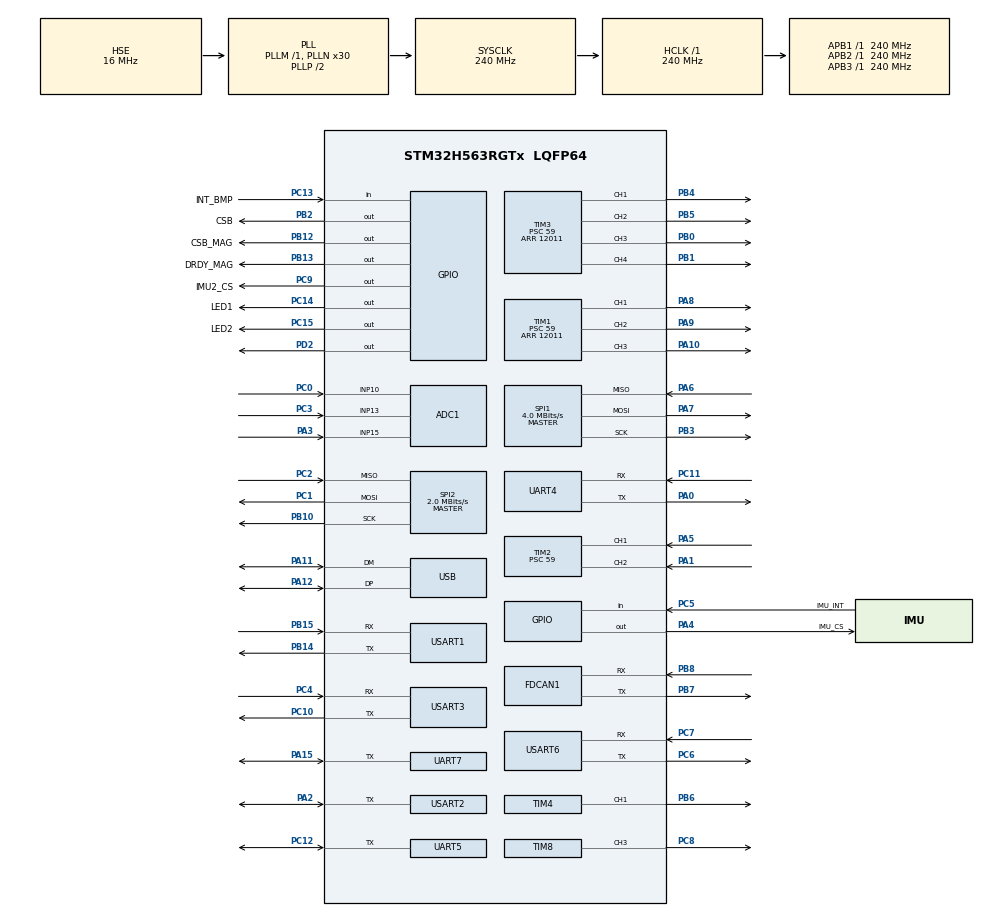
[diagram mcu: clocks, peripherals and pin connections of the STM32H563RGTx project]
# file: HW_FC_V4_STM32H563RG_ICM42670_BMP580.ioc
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ADC1.Channel-0\#ChannelRegularConversion=ADC_CHANNEL_13
ADC1.MonitoredBy-0\#ChannelRegularConversion=__NULL
ADC1.NbrOfConversionFlag=1
ADC1.OffsetNumber-0\#ChannelRegularConversion=ADC_OFFSET_NONE
ADC1.Rank-0\#ChannelRegularConversion=1
ADC1.SamplingTime-0\#ChannelRegularConversion=ADC_SAMPLETIME_2CYCLES_5
ADC1.master=1
BOOTPATH.BootPathName=LEGACY
BOOTPATH.UserSelectedBootPath=LEGACY
CORTEX_M33_NS.userName=CORTEX_M33
FDCAN1.CalculateBaudRateNominal=333333
FDCAN1.CalculateTimeBitNominal=3000
FDCAN1.CalculateTimeQuantumNominal=1000.0
Mcu.Family=STM32H5
Mcu.Name=STM32H563RGTx
Mcu.Package=LQFP64
NVIC.PriorityGroup=NVIC_PRIORITYGROUP_4
NVIC.USART1_IRQn=true\:0\:0\:false\:false\:true\:true\:true\:true
NVIC.USART2_IRQn=true\:0\:0\:false\:false\:true\:true\:true\:true
PA0.Mode=Asynchronous
PA0.Signal=UART4_TX
PA1.Signal=S_TIM2_CH2
PA10.Signal=S_TIM1_CH3
PA11.Mode=Device
PA11.Signal=USB_DM
PA12.Mode=Device
PA12.Signal=USB_DP
PA13(JTMS/SWDIO).Signal=DEBUG_JTMS-SWDIO
PA14(JTCK/SWCLK).Signal=DEBUG_JTCK-SWCLK
PA15(JTDI).Mode=Half_duplex(single_wire_mode)
PA15(JTDI).Signal=UART7_TX
PA2.Mode=Half_duplex(single_wire_mode)
PA2.Signal=USART2_TX
PA3.Signal=ADCx_INP15
PA4.GPIO_Label=IMU_CS
PA4.Signal=GPIO_Output
PA5.Signal=S_TIM2_CH1
PA6.Mode=Full_Duplex_Master
PA6.Signal=SPI1_MISO
PA7.Mode=Full_Duplex_Master
PA7.Signal=SPI1_MOSI
PA8.Signal=S_TIM1_CH1
PA9.Signal=S_TIM1_CH2
PB0.Signal=S_TIM3_CH3
PB1.Signal=S_TIM3_CH4
PB10.Mode=Full_Duplex_Master
PB10.Signal=SPI2_SCK
PB12.GPIO_Label=CSB_MAG
PB12.Signal=GPIO_Output
PB13.GPIO_Label=DRDY_MAG
PB13.Signal=GPIO_Output
PB14.Mode=Asynchronous
PB14.Signal=USART1_TX
PB15.Mode=Asynchronous
PB15.Signal=USART1_RX
PB2.GPIO_Label=CSB
PB2.Signal=GPIO_Output
PB3(JTDO/TRACESWO).Mode=Full_Duplex_Master
PB3(JTDO/TRACESWO).Signal=SPI1_SCK
PB4(NJTRST).PinAttribute=Free
PB4(NJTRST).Signal=S_TIM3_CH1
PB5.PinAttribute=Free
PB5.Signal=S_TIM3_CH2
PB6.PinAttribute=Free
PB6.Signal=S_TIM4_CH1
PB7.Mode=FDCAN_Activate
PB7.Signal=FDCAN1_TX
PB8.Mode=FDCAN_Activate
PB8.Signal=FDCAN1_RX
PC0.Signal=ADCx_INP10
PC1.Mode=Full_Duplex_Master
PC1.Signal=SPI2_MOSI
PC10.Mode=Asynchronous
PC10.Signal=USART3_TX
PC11.Mode=Asynchronous
PC11.Signal=UART4_RX
PC12.Mode=Half_duplex(single_wire_mode)
PC12.Signal=UART5_TX
PC13.GPIO_Label=INT_BMP
PC13.Signal=GPIO_Input
PC14-OSC32_IN(OSC32_IN).GPIO_Label=LED1
PC14-OSC32_IN(OSC32_IN).Signal=GPIO_Output
PC15-OSC32_OUT(OSC32_OUT).GPIO_Label=LED2
PC15-OSC32_OUT(OSC32_OUT).Signal=GPIO_Output
PC2.Mode=Full_Duplex_Master
PC2.Signal=SPI2_MISO
PC3.Signal=ADCx_INP13
PC4.Mode=Asynchronous
PC4.Signal=USART3_RX
PC5.GPIO_Label=IMU_INT
PC5.Signal=GPIO_Input
PC6.Mode=Asynchronous
PC6.Signal=USART6_TX
PC7.Mode=Asynchronous
PC7.Signal=USART6_RX
PC8.Signal=S_TIM8_CH3
PC9.GPIO_Label=IMU2_CS
PC9.Signal=GPIO_Output
PD2.Signal=GPIO_Output
PH0-OSC_IN(PH0).Mode=HSE-External-Oscillator
PH0-OSC_IN(PH0).Signal=RCC_OSC_IN
PH1-OSC_OUT(PH1).Mode=HSE-External-Oscillator
PH1-OSC_OUT(PH1).Signal=RCC_OSC_OUT
ProjectManager.HeapSize=0x200
ProjectManager.StackSize=0x400
ProjectManager.TargetToolchain=STM32CubeIDE
RCC.ADCFreq_Value=240000000
RCC.AHBFreq_Value=240000000
RCC.APB1Freq_Value=240000000
RCC.APB1TimFreq_Value=240000000
RCC.APB2Freq_Value=240000000
RCC.APB2TimFreq_Value=240000000
RCC.APB3Freq_Value=240000000
RCC.CSI_VALUE=4000000
RCC.CortexFreq_Value=240000000
RCC.EPOD_VALUE=16000000
RCC.FLatency=FLASH_LATENCY_5
RCC.FLatency-AdvancedSettings=FLASH_LATENCY_5
RCC.HCLKFreq_Value=240000000
RCC.HSE_VALUE=16000000
RCC.HSI48_VALUE=48000000
RCC.HSI_VALUE=64000000
RCC.LSE_VALUE=32768
RCC.LSIRC_VALUE=32000
RCC.PLL1Q=4
RCC.PLL2Source=RCC_PLL2_SOURCE_HSI
RCC.PLLFRACN=0
RCC.PLLN=30
RCC.PLLSourceVirtual=RCC_PLL1_SOURCE_HSE
RCC.SPI1CLockSelection=RCC_SPI1CLKSOURCE_CLKP
RCC.SPI2CLockSelection=RCC_SPI2CLKSOURCE_CLKP
RCC.SYSCLKFreq_VALUE=240000000
RCC.SYSCLKSource=RCC_SYSCLKSOURCE_PLLCLK
RCC.USBFreq_Value=48000000
RCC.VCOOutputFreq_Value=480000000
SH.ADCx_INP10.0=ADC1_INP10,IN10-Single-Ended
SH.ADCx_INP13.0=ADC1_INP13,IN13-Single-Ended
SH.ADCx_INP15.0=ADC1_INP15,IN15-Single-Ended
SH.S_TIM1_CH1.0=TIM1_CH1,PWM Generation1 CH1
SH.S_TIM1_CH2.0=TIM1_CH2,PWM Generation2 CH2
SH.S_TIM1_CH3.0=TIM1_CH3,PWM Generation3 CH3
SH.S_TIM2_CH1.0=TIM2_CH1,Input_Capture1_from_TI1
SH.S_TIM2_CH2.0=TIM2_CH2,Input_Capture2_from_TI2
SH.S_TIM3_CH1.0=TIM3_CH1,PWM Generation1 CH1
SH.S_TIM3_CH2.0=TIM3_CH2,PWM Generation2 CH2
SH.S_TIM3_CH3.0=TIM3_CH3,PWM Generation3 CH3
SH.S_TIM3_CH4.0=TIM3_CH4,PWM Generation4 CH4
SH.S_TIM4_CH1.0=TIM4_CH1,PWM Generation1 CH1
SH.S_TIM8_CH3.0=TIM8_CH3,PWM Generation3 CH3
SPI1.BaudRatePrescaler=SPI_BAUDRATEPRESCALER_8
SPI1.CLKPhase=SPI_PHASE_1EDGE
SPI1.CLKPolarity=SPI_POLARITY_LOW
SPI1.CalculateBaudRate=4.0 MBits/s
SPI1.DataSize=SPI_DATASIZE_8BIT
SPI1.Direction=SPI_DIRECTION_2LINES
SPI1.Mode=SPI_MODE_MASTER
SPI1.VirtualType=VM_MASTER
SPI2.BaudRatePrescaler=SPI_BAUDRATEPRESCALER_16
SPI2.CalculateBaudRate=2.0 MBits/s
SPI2.DataSize=SPI_DATASIZE_8BIT
SPI2.Direction=SPI_DIRECTION_2LINES
SPI2.Mode=SPI_MODE_MASTER
SPI2.VirtualType=VM_MASTER
TIM1.Channel-PWM\ Generation1\ CH1=TIM_CHANNEL_1
TIM1.Channel-PWM\ Generation2\ CH2=TIM_CHANNEL_2
TIM1.Channel-PWM\ Generation3\ CH3=TIM_CHANNEL_3
TIM1.PeriodNoDither=12011
TIM1.Prescaler=59
TIM2.Channel-Input_Capture1_from_TI1=TIM_CHANNEL_1
TIM2.Channel-Input_Capture2_from_TI2=TIM_CHANNEL_2
TIM2.Prescaler=59
TIM3.Channel-PWM\ Generation1\ CH1=TIM_CHANNEL_1
TIM3.Channel-PWM\ Generation2\ CH2=TIM_CHANNEL_2
TIM3.Channel-PWM\ Generation3\ CH3=TIM_CHANNEL_3
TIM3.Channel-PWM\ Generation4\ CH4=TIM_CHANNEL_4
TIM3.PeriodNoDither=12011
TIM3.Prescaler=59
TIM4.Channel-PWM\ Generation1\ CH1=TIM_CHANNEL_1
TIM4.PeriodNoDither=7142
TIM4.Prescaler=59
TIM8.Channel-PWM\ Generation3\ CH3=TIM_CHANNEL_3
TIM8.PeriodNoDither=12011
TIM8.Prescaler=59
USART1.VirtualMode-Asynchronous=VM_ASYNC
USART2.VirtualMode-Half_duplex(single_wire_mode)=VM_ASYNC
USART3.VirtualMode-Asynchronous=VM_ASYNC
USART6.VirtualMode=VM_ASYNC
USB.VirtualMode=Device_Only
USBX.Core_System=1
USBX.USBD_CDCACM_EPIN_ADDR=2
USBX.USBD_CDCACM_EPOUT_ADDR=3
USBX.UX_DEVICE_CDC_ACM=1
USBX.UX_DEVICE_ENABLED_FS=1
USBX.UX_Device_CoreStack=1
USBX.UX_enabled_FS=1
VP_BOOTPATH_VS_BOOTPATH.Mode=BP_Activate
VP_CORTEX_M33_NS_VS_Hclk.Mode=Hclk_Mode
VP_GPDMA1_VS_GPDMACH0.Mode=SIMPLEREQUEST_GPDMACH0
VP_ICACHE_VS_ICACHE.Mode=DefaultMode
VP_MEMORYMAP_VS_MEMORYMAP.Mode=CurAppReg
VP_PWR_VS_LPOM.Mode=PowerOptimisation
VP_PWR_VS_SECSignals.Mode=Security/Privilege
VP_TIM1_VS_ClockSourceINT.Mode=Internal
VP_TIM2_VS_ClockSourceINT.Mode=Internal
VP_TIM3_VS_ClockSourceINT.Mode=Internal
VP_TIM4_VS_ClockSourceINT.Mode=Internal
VP_TIM8_VS_ClockSourceINT.Mode=Internal
VP_USBX_Core_System.Mode=Core_System
VP_USBX_UX\ Device\ CDC\ ACM\ Class_FS.Mode=UX_Device_class_CDC_ACM_FS_HS
VP_USBX_UX\ Device\ CoreStack_FS.Mode=UX_Device_CoreStack
board=custom

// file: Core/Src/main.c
/* USER CODE BEGIN Header */
/**
  ******************************************************************************
  * @file           : main.c
  * @brief          : Main program body
  ******************************************************************************
  * @attention
  *
  * Copyright (c) 2026 STMicroelectronics.
  * All rights reserved.
  *
  * This software is licensed under terms that can be found in the LICENSE file
  * in the root directory of this software component.
  * If no LICENSE file comes with this software, it is provided AS-IS.
  *
  ******************************************************************************
  */
/* USER CODE END Header */
#include "main.h"
#include "app_usbx.h"

/* USER CODE BEGIN Includes */
#include "bmp5.h"
#include "math.h"
#include "bmm150.h"
/* USER CODE END Includes */

ADC_HandleTypeDef hadc1;

FDCAN_HandleTypeDef hfdcan1;

DMA_HandleTypeDef handle_GPDMA1_Channel0;

TIM_HandleTypeDef htim8;

UART_HandleTypeDef huart4;
UART_HandleTypeDef huart5;
UART_HandleTypeDef huart7;
UART_HandleTypeDef huart1;
UART_HandleTypeDef huart2;
UART_HandleTypeDef huart3;
UART_HandleTypeDef huart6;

PCD_HandleTypeDef hpcd_USB_DRD_FS;

/* USER CODE BEGIN PV */
static struct bmp5_dev bmp580_dev;
static struct bmp5_osr_odr_press_config bmp580_cfg;
static volatile int8_t bmp580_init_status;
static volatile int8_t bmp580_read_status;
static volatile uint8_t bmp580_spi_error_stage;
static volatile uint8_t bmp580_spi_last_rx;
static float bmp580_temperature_c;
static float bmp580_pressure_pa;
static struct bmm150_dev bmm150_dev;
static volatile int8_t bmm150_init_status;
static volatile int8_t bmm150_read_status;
static int16_t bmm150_x;
static int16_t bmm150_y;
static int16_t bmm150_z;
static float bmm150_heading_deg;
static uint32_t bmp580_last_read_ms;
static uint32_t bmm150_last_read_ms;
/* USER CODE END PV */

void SystemClock_Config(void);
void PeriphCommonClock_Config(void);
static void MX_GPIO_Init(void);
static void MX_GPDMA1_Init(void);
static void MX_SPI1_Init(void);
static void MX_SPI2_Init(void);
static void MX_TIM1_Init(void);
static void MX_TIM2_Init(void);
static void MX_TIM3_Init(void);
static void MX_TIM4_Init(void);
static void MX_UART4_Init(void);
static void MX_UART5_Init(void);
static void MX_USART1_UART_Init(void);
static void MX_USART2_UART_Init(void);
static void MX_USART3_UART_Init(void);
static void MX_USB_PCD_Init(void);
static void MX_ADC1_Init(void);
static void MX_FDCAN1_Init(void);
static void MX_TIM8_Init(void);
static void MX_UART7_Init(void);
static void MX_USART6_UART_Init(void);
static void MX_ICACHE_Init(void);

/* USER CODE BEGIN 0 */
/*
 * BMP580 connection (SPI2):
 * PB10 = SCK
 * PC1  = MOSI / SDI
 * PC2  = MISO / SDO
 * PB2  = CSB (active LOW)
 * PC13 = INT_BMP (currently not used; polling mode is used)
 *
 * SPI mode: CPOL = LOW, CPHA = 1st edge, 8-bit, MSB first.
 */
#define BMP580_SPI_TIMEOUT  100000U
static void bmp580_spi_clear_flags(void)
{
    LL_SPI_ClearFlag_EOT(SPI1);
    LL_SPI_ClearFlag_TXTF(SPI1);
    LL_SPI_ClearFlag_UDR(SPI1);
    LL_SPI_ClearFlag_OVR(SPI1);
    LL_SPI_ClearFlag_FRE(SPI1);
    LL_SPI_ClearFlag_MODF(SPI1);
    LL_SPI_ClearFlag_SUSP(SPI1);
}
static void bmp580_spi_abort(void)
{
    LL_GPIO_SetOutputPin(CSB_GPIO_Port, CSB_Pin); /* CSB = 1 */

    LL_SPI_Disable(SPI1);
    bmp580_spi_clear_flags();
}

static int8_t bmp580_spi_start(uint32_t bytes)
{
    LL_SPI_Disable(SPI1);
    bmp580_spi_clear_flags();
    LL_SPI_SetTransferSize(SPI1, bytes);
    LL_GPIO_ResetOutputPin(CSB_GPIO_Port, CSB_Pin); /* CSB = 0 */
    LL_SPI_Enable(SPI1);
    LL_SPI_StartMasterTransfer(SPI1);
    return 0;
}

static int8_t bmp580_spi_txrx_byte(uint8_t tx, uint8_t *rx)
{
    uint32_t timeout = BMP580_SPI_TIMEOUT;

    while (!LL_SPI_IsActiveFlag_TXP(SPI1))
    {
        if (--timeout == 0U)
        {
            bmp580_spi_error_stage = 1;  /* TXP timeout */
            return -1;
        }
    }

    LL_SPI_TransmitData8(SPI1, tx);

    timeout = BMP580_SPI_TIMEOUT;

    while (!LL_SPI_IsActiveFlag_RXP(SPI1))
    {
        if (--timeout == 0U)
        {
            bmp580_spi_error_stage = 2;  /* RXP timeout */
            return -1;
        }
    }

    *rx = LL_SPI_ReceiveData8(SPI1);
    bmp580_spi_last_rx = *rx;
    return 0;
}

static int8_t bmp580_spi_finish(void)
{
    uint32_t timeout = BMP580_SPI_TIMEOUT;
    while (!LL_SPI_IsActiveFlag_EOT(SPI1))
    {
        if (--timeout == 0U)
        {
            bmp580_spi_error_stage = 3;
            bmp580_spi_abort();
            return -1;
        }
    }
    LL_GPIO_SetOutputPin(CSB_GPIO_Port, CSB_Pin); /* CSB = 1 */
    LL_SPI_ClearFlag_EOT(SPI1);
    LL_SPI_ClearFlag_TXTF(SPI1);
    LL_SPI_Disable(SPI1);

    return 0;
}

static BMP5_INTF_RET_TYPE bmp580_spi_read(uint8_t reg_addr,  uint8_t *data, uint32_t len,
void *intf_ptr)
{
    uint8_t dummy;
    uint32_t i;
    (void)intf_ptr;
    if ((data == NULL) || (len == 0U)) return -1;
    if (bmp580_spi_start(len + 1U) != 0) return -1;
    if (bmp580_spi_txrx_byte(reg_addr, &dummy) != 0)
    {
        bmp580_spi_abort();return -1;
    }

    for (i = 0; i < len; i++)
    {
        if (bmp580_spi_txrx_byte(0x00U, &data[i]) != 0)
        {
            bmp580_spi_abort();
            return -1;
        }
    }

    return bmp580_spi_finish();
}

static BMP5_INTF_RET_TYPE bmp580_spi_write(uint8_t reg_addr, const uint8_t *data, uint32_t len, void *intf_ptr)
{
    uint8_t dummy;
    uint32_t i;
    (void)intf_ptr;
    if ((data == NULL) || (len == 0U))
        return -1;
    if (bmp580_spi_start(len + 1U) != 0)
        return -1;
    if (bmp580_spi_txrx_byte(reg_addr, &dummy) != 0)
    {
        bmp580_spi_abort();
        return -1;
    }
    for (i = 0; i < len; i++)
    {
        if (bmp580_spi_txrx_byte(data[i], &dummy) != 0)
        {
            bmp580_spi_abort();
            return -1;
        }
    }
    return bmp580_spi_finish();
}

static void bmp580_delay_us(uint32_t period, void *intf_ptr)
{
    (void)intf_ptr;

    if (period > 0U)
        HAL_Delay((period + 999U) / 1000U);
}
static int8_t BMP580_Init(void)
{
    int8_t rslt;
    struct bmp5_iir_config iir_cfg = {0};
    LL_GPIO_SetOutputPin(CSB_GPIO_Port, CSB_Pin);
    bmp580_dev.intf = BMP5_SPI_INTF;
    bmp580_dev.read = bmp580_spi_read;
    bmp580_dev.write = bmp580_spi_write;
    bmp580_dev.delay_us = bmp580_delay_us;
    bmp580_dev.intf_ptr = NULL;
    rslt = bmp5_init(&bmp580_dev);
    if (rslt == BMP5_E_NVM_NOT_READY)
    {
        uint8_t chip_id = 0;

        rslt = bmp5_get_regs(BMP5_REG_CHIP_ID, &chip_id, 1U, &bmp580_dev);

        if ((rslt == BMP5_OK) &&
            ((chip_id == BMP5_CHIP_ID_PRIM) || (chip_id == BMP5_CHIP_ID_SEC)))
        {
            bmp580_dev.chip_id = chip_id;
            rslt = BMP5_OK;
        }
    }

    if (rslt != BMP5_OK)
        return rslt;
    rslt = bmp5_set_power_mode(BMP5_POWERMODE_STANDBY, &bmp580_dev);
    if (rslt != BMP5_OK)
        return rslt;

    bmp580_cfg.press_en = BMP5_ENABLE;
    bmp580_cfg.osr_t = BMP5_OVERSAMPLING_64X;
    bmp580_cfg.osr_p = BMP5_OVERSAMPLING_4X;
    bmp580_cfg.odr = BMP5_ODR_50_HZ;

    rslt = bmp5_set_osr_odr_press_config(&bmp580_cfg, &bmp580_dev);
    if (rslt != BMP5_OK)
        return rslt;

    iir_cfg.set_iir_t = BMP5_IIR_FILTER_COEFF_1;
    iir_cfg.set_iir_p = BMP5_IIR_FILTER_COEFF_1;
    iir_cfg.shdw_set_iir_t = BMP5_ENABLE;
    iir_cfg.shdw_set_iir_p = BMP5_ENABLE;

    rslt = bmp5_set_iir_config(&iir_cfg, &bmp580_dev);
    if (rslt != BMP5_OK)
        return rslt;

    return bmp5_set_power_mode(BMP5_POWERMODE_NORMAL, &bmp580_dev);
}

static int8_t BMP580_Read(float *temperature_c, float *pressure_pa)
{
    struct bmp5_sensor_data data;
    int8_t rslt;

    rslt = bmp5_get_sensor_data(&data, &bmp580_cfg, &bmp580_dev);
    if (rslt == BMP5_OK)
    {
        *temperature_c = data.temperature;
        *pressure_pa = data.pressure;
    }

    return rslt;
}
static void bmm150_spi_abort(void)
{
    LL_GPIO_SetOutputPin(CSB_MAG_GPIO_Port, CSB_MAG_Pin);
    LL_SPI_Disable(SPI1);
    bmp580_spi_clear_flags();
}

static int8_t bmm150_spi_start(uint32_t bytes)
{
    if ((bytes == 0U) || (bytes > 65535U))
        return BMM150_E_COM_FAIL;

    LL_SPI_Disable(SPI1);
    bmp580_spi_clear_flags();
    LL_SPI_SetTransferSize(SPI1, bytes);

    LL_GPIO_SetOutputPin(CSB_GPIO_Port, CSB_Pin);
    LL_GPIO_SetOutputPin(IMU_CS_GPIO_Port, IMU_CS_Pin);
    LL_GPIO_SetOutputPin(GPIOC, IMU2_CS_Pin);

    LL_GPIO_ResetOutputPin(CSB_MAG_GPIO_Port, CSB_MAG_Pin);

    LL_SPI_Enable(SPI1);
    LL_SPI_StartMasterTransfer(SPI1);

    return BMM150_OK;
}

static int8_t bmm150_spi_finish(void)
{
    uint32_t timeout = BMP580_SPI_TIMEOUT;

    while (!LL_SPI_IsActiveFlag_EOT(SPI1))
    {
        if (--timeout == 0U)
        {
            bmm150_spi_abort();
            return BMM150_E_COM_FAIL;
        }
    }

    LL_GPIO_SetOutputPin(CSB_MAG_GPIO_Port, CSB_MAG_Pin);
    LL_SPI_ClearFlag_EOT(SPI1);
    LL_SPI_ClearFlag_TXTF(SPI1);
    LL_SPI_Disable(SPI1);

    return BMM150_OK;
}

static BMM150_INTF_RET_TYPE bmm150_spi_read(uint8_t reg_addr, uint8_t *data, uint32_t len, void *intf_ptr)
{
    uint8_t dummy;
    uint32_t i;

    (void)intf_ptr;

    if ((data == NULL) || (len == 0U))
        return BMM150_E_NULL_PTR;

    if (bmm150_spi_start(len + 1U) != BMM150_OK)
        return BMM150_E_COM_FAIL;

    /* BMM150 library da tu them bit read 0x80 */
    if (bmp580_spi_txrx_byte(reg_addr, &dummy) != 0)
    {
        bmm150_spi_abort();
        return BMM150_E_COM_FAIL;
    }

    for (i = 0U; i < len; i++)
    {
        if (bmp580_spi_txrx_byte(0x00U, &data[i]) != 0)
        {
            bmm150_spi_abort();
            return BMM150_E_COM_FAIL;
        }
    }

    return bmm150_spi_finish();
}

static BMM150_INTF_RET_TYPE bmm150_spi_write(uint8_t reg_addr, const uint8_t *data, uint32_t len, void *intf_ptr)
{
    uint8_t dummy;
    uint32_t i;

    (void)intf_ptr;

    if ((data == NULL) || (len == 0U))
        return BMM150_E_NULL_PTR;

    if (bmm150_spi_start(len + 1U) != BMM150_OK)
        return BMM150_E_COM_FAIL;

    if (bmp580_spi_txrx_byte(reg_addr, &dummy) != 0)
    {
        bmm150_spi_abort();
        return BMM150_E_COM_FAIL;
    }

    for (i = 0U; i < len; i++)
    {
        if (bmp580_spi_txrx_byte(data[i], &dummy) != 0)
        {
            bmm150_spi_abort();
            return BMM150_E_COM_FAIL;
        }
    }

    return bmm150_spi_finish();
}

static int8_t BMM150_Init(void)
{
    int8_t rslt;
    struct bmm150_settings settings = {0};

    LL_GPIO_SetOutputPin(CSB_MAG_GPIO_Port, CSB_MAG_Pin);

    bmm150_dev.intf = BMM150_SPI_INTF;
    bmm150_dev.read = bmm150_spi_read;
    bmm150_dev.write = bmm150_spi_write;
    bmm150_dev.delay_us = bmp580_delay_us;
    bmm150_dev.intf_ptr = &bmm150_dev;

    rslt = bmm150_init(&bmm150_dev);

    if ((rslt != BMM150_OK) ||
        (bmm150_dev.chip_id != BMM150_CHIP_ID))
    {
        return BMM150_E_DEV_NOT_FOUND;
    }

    settings.preset_mode = BMM150_PRESETMODE_REGULAR;
    rslt = bmm150_set_presetmode(&settings, &bmm150_dev);
    if (rslt != BMM150_OK)
        return rslt;

    settings.pwr_mode = BMM150_POWERMODE_NORMAL;
    return bmm150_set_op_mode(&settings, &bmm150_dev);
}

static int8_t BMM150_Read(int16_t *x, int16_t *y, int16_t *z)
{
    struct bmm150_mag_data data;
    int8_t rslt;

    rslt = bmm150_read_mag_data(&data, &bmm150_dev);

    if (rslt == BMM150_OK)
    {
        *x = data.x;
        *y = data.y;
        *z = data.z;
    }

    return rslt;
}

static void BMM150_UpdateHeading(void)
{
    if ((bmm150_x != BMM150_OVERFLOW_OUTPUT) &&
        (bmm150_y != BMM150_OVERFLOW_OUTPUT))
    {
        bmm150_heading_deg =
            atan2f((float)bmm150_y, (float)bmm150_x) * 57.2957795f;

        if (bmm150_heading_deg < 0.0f)
            bmm150_heading_deg += 360.0f;
    }
}
/* USER CODE END 0 */

int main(void)
{

  /* MCU Configuration--------------------------------------------------------*/

  /* Reset of all peripherals, Initializes the Flash interface and the Systick. */
  HAL_Init();

  /* Configure the system clock */
  SystemClock_Config();

  /* Configure the peripherals common clocks */
  PeriphCommonClock_Config();

  /* Initialize all configured peripherals */
  MX_GPIO_Init();
  MX_GPDMA1_Init();
  MX_SPI1_Init();
  MX_SPI2_Init();
  MX_TIM1_Init();
  MX_TIM2_Init();
  MX_TIM3_Init();
  MX_TIM4_Init();
  MX_UART4_Init();
  MX_UART5_Init();
  MX_USART1_UART_Init();
  MX_USART2_UART_Init();
  MX_USART3_UART_Init();
  MX_USB_PCD_Init();
  MX_ADC1_Init();
  MX_FDCAN1_Init();
  MX_TIM8_Init();
  MX_UART7_Init();
//  MX_USBX_Init();
  MX_USART6_UART_Init();
  MX_ICACHE_Init();
  /* USER CODE BEGIN 2 */
  /* Deselect every SPI1 sensor before communicating with BMP580 */
  LL_GPIO_SetOutputPin(CSB_GPIO_Port, CSB_Pin);
  LL_GPIO_SetOutputPin(CSB_MAG_GPIO_Port, CSB_MAG_Pin);
  LL_GPIO_SetOutputPin(IMU_CS_GPIO_Port, IMU_CS_Pin);
  LL_GPIO_SetOutputPin(GPIOC, IMU2_CS_Pin);

  HAL_Delay(100);

  bmp580_spi_error_stage = 0;
  bmp580_init_status = BMP580_Init();
  bmm150_init_status = BMM150_Init();

  if (bmm150_init_status != BMM150_OK)
  {
      Error_Handler();
  }
  if (bmp580_init_status != BMP5_OK)
  {
      Error_Handler();
  }

  HAL_Delay(25);
  /* USER CODE END 2 */

  /* Infinite loop */
  while (1)
  {
    /* USER CODE BEGIN 3 */
	  uint32_t now_ms = HAL_GetTick();

	  /* BMP580: đọc 50 Hz */
	  if ((uint32_t)(now_ms - bmp580_last_read_ms) >= 20U)
	  {
	      bmp580_last_read_ms = now_ms;
	      bmp580_read_status = BMP580_Read(&bmp580_temperature_c, &bmp580_pressure_pa);
	  }
	  /* BMM150: đọc 10 Hz, đúng ODR Regular mode */
	  if ((uint32_t)(now_ms - bmm150_last_read_ms) >= 100U)
	  {
	      bmm150_last_read_ms = now_ms;
	      bmm150_read_status = BMM150_Read(&bmm150_x, &bmm150_y, &bmm150_z);
	      if (bmm150_read_status == BMM150_OK)
	      {
	          BMM150_UpdateHeading();
	      }
	  }
  }
  /* USER CODE END 3 */
}

void SystemClock_Config(void)
{
  RCC_OscInitTypeDef RCC_OscInitStruct = {0};
  RCC_ClkInitTypeDef RCC_ClkInitStruct = {0};

  /** Configure the main internal regulator output voltage
  */
  __HAL_PWR_VOLTAGESCALING_CONFIG(PWR_REGULATOR_VOLTAGE_SCALE0);

  while(!__HAL_PWR_GET_FLAG(PWR_FLAG_VOSRDY)) {}

  /** Initializes the RCC Oscillators according to the specified parameters
  * in the RCC_OscInitTypeDef structure.
  */
  RCC_OscInitStruct.OscillatorType = RCC_OSCILLATORTYPE_HSI48|RCC_OSCILLATORTYPE_LSI
                              |RCC_OSCILLATORTYPE_HSE;
  RCC_OscInitStruct.HSEState = RCC_HSE_ON;
  RCC_OscInitStruct.LSIState = RCC_LSI_ON;
  RCC_OscInitStruct.HSI48State = RCC_HSI48_ON;
  RCC_OscInitStruct.PLL.PLLState = RCC_PLL_ON;
  RCC_OscInitStruct.PLL.PLLSource = RCC_PLL1_SOURCE_HSE;
  RCC_OscInitStruct.PLL.PLLM = 1;
  RCC_OscInitStruct.PLL.PLLN = 30;
  RCC_OscInitStruct.PLL.PLLP = 2;
  RCC_OscInitStruct.PLL.PLLQ = 4;
  RCC_OscInitStruct.PLL.PLLR = 2;
  RCC_OscInitStruct.PLL.PLLRGE = RCC_PLL1_VCIRANGE_3;
  RCC_OscInitStruct.PLL.PLLVCOSEL = RCC_PLL1_VCORANGE_WIDE;
  RCC_OscInitStruct.PLL.PLLFRACN = 0;
  if (HAL_RCC_OscConfig(&RCC_OscInitStruct) != HAL_OK)
  {
    Error_Handler();
  }

  /** Initializes the CPU, AHB and APB buses clocks
  */
  RCC_ClkInitStruct.ClockType = RCC_CLOCKTYPE_HCLK|RCC_CLOCKTYPE_SYSCLK
                              |RCC_CLOCKTYPE_PCLK1|RCC_CLOCKTYPE_PCLK2
                              |RCC_CLOCKTYPE_PCLK3;
  RCC_ClkInitStruct.SYSCLKSource = RCC_SYSCLKSOURCE_PLLCLK;
  RCC_ClkInitStruct.AHBCLKDivider = RCC_SYSCLK_DIV1;
  RCC_ClkInitStruct.APB1CLKDivider = RCC_HCLK_DIV1;
  RCC_ClkInitStruct.APB2CLKDivider = RCC_HCLK_DIV1;
  RCC_ClkInitStruct.APB3CLKDivider = RCC_HCLK_DIV1;

  if (HAL_RCC_ClockConfig(&RCC_ClkInitStruct, FLASH_LATENCY_5) != HAL_OK)
  {
    Error_Handler();
  }

  /** Configure the programming delay
  */
  __HAL_FLASH_SET_PROGRAM_DELAY(FLASH_PROGRAMMING_DELAY_2);
}

void PeriphCommonClock_Config(void)
{
  RCC_PeriphCLKInitTypeDef PeriphClkInitStruct = {0};

  /** Initializes the peripherals clock
  */
  PeriphClkInitStruct.PeriphClockSelection = RCC_PERIPHCLK_CKPER;
  PeriphClkInitStruct.CkperClockSelection = RCC_CLKPSOURCE_HSI;
  if (HAL_RCCEx_PeriphCLKConfig(&PeriphClkInitStruct) != HAL_OK)
  {
    Error_Handler();
  }
}

static void MX_ADC1_Init(void)
{

  ADC_ChannelConfTypeDef sConfig = {0};

  /** Common config
  */
  hadc1.Instance = ADC1;
  hadc1.Init.ClockPrescaler = ADC_CLOCK_ASYNC_DIV4;
  hadc1.Init.Resolution = ADC_RESOLUTION_12B;
  hadc1.Init.DataAlign = ADC_DATAALIGN_RIGHT;
  hadc1.Init.ScanConvMode = ADC_SCAN_DISABLE;
  hadc1.Init.EOCSelection = ADC_EOC_SINGLE_CONV;
  hadc1.Init.LowPowerAutoWait = DISABLE;
  hadc1.Init.ContinuousConvMode = DISABLE;
  hadc1.Init.NbrOfConversion = 1;
  hadc1.Init.DiscontinuousConvMode = DISABLE;
  hadc1.Init.ExternalTrigConv = ADC_SOFTWARE_START;
  hadc1.Init.ExternalTrigConvEdge = ADC_EXTERNALTRIGCONVEDGE_NONE;
  hadc1.Init.DMAContinuousRequests = DISABLE;
  hadc1.Init.SamplingMode = ADC_SAMPLING_MODE_NORMAL;
  hadc1.Init.Overrun = ADC_OVR_DATA_PRESERVED;
  hadc1.Init.OversamplingMode = DISABLE;
  if (HAL_ADC_Init(&hadc1) != HAL_OK)
  {
    Error_Handler();
  }

  /** Configure Regular Channel
  */
  sConfig.Channel = ADC_CHANNEL_13;
  sConfig.Rank = ADC_REGULAR_RANK_1;
  sConfig.SamplingTime = ADC_SAMPLETIME_2CYCLES_5;
  sConfig.SingleDiff = ADC_SINGLE_ENDED;
  sConfig.OffsetNumber = ADC_OFFSET_NONE;
  sConfig.Offset = 0;
  if (HAL_ADC_ConfigChannel(&hadc1, &sConfig) != HAL_OK)
  {
    Error_Handler();
  }

}

static void MX_FDCAN1_Init(void)
{

  hfdcan1.Instance = FDCAN1;
  hfdcan1.Init.ClockDivider = FDCAN_CLOCK_DIV1;
  hfdcan1.Init.FrameFormat = FDCAN_FRAME_CLASSIC;
  hfdcan1.Init.Mode = FDCAN_MODE_NORMAL;
  hfdcan1.Init.AutoRetransmission = DISABLE;
  hfdcan1.Init.TransmitPause = DISABLE;
  hfdcan1.Init.ProtocolException = DISABLE;
  hfdcan1.Init.NominalPrescaler = 16;
  hfdcan1.Init.NominalSyncJumpWidth = 1;
  hfdcan1.Init.NominalTimeSeg1 = 1;
  hfdcan1.Init.NominalTimeSeg2 = 1;
  hfdcan1.Init.DataPrescaler = 1;
  hfdcan1.Init.DataSyncJumpWidth = 1;
  hfdcan1.Init.DataTimeSeg1 = 1;
  hfdcan1.Init.DataTimeSeg2 = 1;
  hfdcan1.Init.StdFiltersNbr = 0;
  hfdcan1.Init.ExtFiltersNbr = 0;
  hfdcan1.Init.TxFifoQueueMode = FDCAN_TX_FIFO_OPERATION;
  if (HAL_FDCAN_Init(&hfdcan1) != HAL_OK)
  {
    Error_Handler();
  }

}

static void MX_GPDMA1_Init(void)
{

  /* Peripheral clock enable */
  __HAL_RCC_GPDMA1_CLK_ENABLE();

  handle_GPDMA1_Channel0.Instance = GPDMA1_Channel0;
  handle_GPDMA1_Channel0.Init.Request = DMA_REQUEST_SW;
  handle_GPDMA1_Channel0.Init.BlkHWRequest = DMA_BREQ_SINGLE_BURST;
  handle_GPDMA1_Channel0.Init.Direction = DMA_MEMORY_TO_MEMORY;
  handle_GPDMA1_Channel0.Init.SrcInc = DMA_SINC_FIXED;
  handle_GPDMA1_Channel0.Init.DestInc = DMA_DINC_FIXED;
  handle_GPDMA1_Channel0.Init.SrcDataWidth = DMA_SRC_DATAWIDTH_BYTE;
  handle_GPDMA1_Channel0.Init.DestDataWidth = DMA_DEST_DATAWIDTH_BYTE;
  handle_GPDMA1_Channel0.Init.Priority = DMA_LOW_PRIORITY_LOW_WEIGHT;
  handle_GPDMA1_Channel0.Init.SrcBurstLength = 1;
  handle_GPDMA1_Channel0.Init.DestBurstLength = 1;
  handle_GPDMA1_Channel0.Init.TransferAllocatedPort = DMA_SRC_ALLOCATED_PORT0|DMA_DEST_ALLOCATED_PORT0;
  handle_GPDMA1_Channel0.Init.TransferEventMode = DMA_TCEM_BLOCK_TRANSFER;
  handle_GPDMA1_Channel0.Init.Mode = DMA_NORMAL;
  if (HAL_DMA_Init(&handle_GPDMA1_Channel0) != HAL_OK)
  {
    Error_Handler();
  }
  if (HAL_DMA_ConfigChannelAttributes(&handle_GPDMA1_Channel0, DMA_CHANNEL_NPRIV) != HAL_OK)
  {
    Error_Handler();
  }

}

static void MX_ICACHE_Init(void)
{

  /** Enable instruction cache (default 2-ways set associative cache)
  */
  if (HAL_ICACHE_Enable() != HAL_OK)
  {
    Error_Handler();
  }

}

static void MX_SPI1_Init(void)
{

  LL_SPI_InitTypeDef SPI_InitStruct = {0};

  LL_GPIO_InitTypeDef GPIO_InitStruct = {0};
  RCC_PeriphCLKInitTypeDef PeriphClkInitStruct = {0};

  /** Initializes the peripherals clock
  */
  PeriphClkInitStruct.PeriphClockSelection = RCC_PERIPHCLK_SPI1;
  PeriphClkInitStruct.Spi1ClockSelection = RCC_SPI1CLKSOURCE_CLKP;
  if (HAL_RCCEx_PeriphCLKConfig(&PeriphClkInitStruct) != HAL_OK)
  {
    Error_Handler();
  }

  /* Peripheral clock enable */
  LL_APB2_GRP1_EnableClock(LL_APB2_GRP1_PERIPH_SPI1);

  LL_AHB2_GRP1_EnableClock(LL_AHB2_GRP1_PERIPH_GPIOA);
  LL_AHB2_GRP1_EnableClock(LL_AHB2_GRP1_PERIPH_GPIOB);
  /**SPI1 GPIO Configuration
  PA6   ------> SPI1_MISO
  PA7   ------> SPI1_MOSI
  PB3(JTDO/TRACESWO)   ------> SPI1_SCK
  */
  GPIO_InitStruct.Pin = LL_GPIO_PIN_6|LL_GPIO_PIN_7;
  GPIO_InitStruct.Mode = LL_GPIO_MODE_ALTERNATE;
  GPIO_InitStruct.Speed = LL_GPIO_SPEED_FREQ_LOW;
  GPIO_InitStruct.OutputType = LL_GPIO_OUTPUT_PUSHPULL;
  GPIO_InitStruct.Pull = LL_GPIO_PULL_NO;
  GPIO_InitStruct.Alternate = LL_GPIO_AF_5;
  LL_GPIO_Init(GPIOA, &GPIO_InitStruct);

  GPIO_InitStruct.Pin = LL_GPIO_PIN_3;
  GPIO_InitStruct.Mode = LL_GPIO_MODE_ALTERNATE;
  GPIO_InitStruct.Speed = LL_GPIO_SPEED_FREQ_LOW;
  GPIO_InitStruct.OutputType = LL_GPIO_OUTPUT_PUSHPULL;
  GPIO_InitStruct.Pull = LL_GPIO_PULL_NO;
  GPIO_InitStruct.Alternate = LL_GPIO_AF_5;
  LL_GPIO_Init(GPIOB, &GPIO_InitStruct);

  /* SPI1 parameter configuration*/
  SPI_InitStruct.TransferDirection = LL_SPI_FULL_DUPLEX;
  SPI_InitStruct.Mode = LL_SPI_MODE_MASTER;
  SPI_InitStruct.DataWidth = LL_SPI_DATAWIDTH_8BIT;
  SPI_InitStruct.ClockPolarity = LL_SPI_POLARITY_LOW;
  SPI_InitStruct.ClockPhase = LL_SPI_PHASE_1EDGE;
  SPI_InitStruct.NSS = LL_SPI_NSS_SOFT;
  SPI_InitStruct.BaudRate = LL_SPI_BAUDRATEPRESCALER_DIV8;
  SPI_InitStruct.BitOrder = LL_SPI_MSB_FIRST;
  SPI_InitStruct.CRCCalculation = LL_SPI_CRCCALCULATION_DISABLE;
  SPI_InitStruct.CRCPoly = 0x7;
  LL_SPI_Init(SPI1, &SPI_InitStruct);
  LL_SPI_SetStandard(SPI1, LL_SPI_PROTOCOL_MOTOROLA);
  LL_SPI_EnableNSSPulseMgt(SPI1);
  /* USER CODE BEGIN SPI1_Init 2 */
  LL_SPI_SetFIFOThreshold(SPI1, LL_SPI_FIFO_TH_01DATA);
  /* USER CODE END SPI1_Init 2 */

}

static void MX_SPI2_Init(void)
{

  LL_SPI_InitTypeDef SPI_InitStruct = {0};

  LL_GPIO_InitTypeDef GPIO_InitStruct = {0};
  RCC_PeriphCLKInitTypeDef PeriphClkInitStruct = {0};

  /** Initializes the peripherals clock
  */
  PeriphClkInitStruct.PeriphClockSelection = RCC_PERIPHCLK_SPI2;
  PeriphClkInitStruct.Spi2ClockSelection = RCC_SPI2CLKSOURCE_CLKP;
  if (HAL_RCCEx_PeriphCLKConfig(&PeriphClkInitStruct) != HAL_OK)
  {
    Error_Handler();
  }

  /* Peripheral clock enable */
  LL_APB1_GRP1_EnableClock(LL_APB1_GRP1_PERIPH_SPI2);

  LL_AHB2_GRP1_EnableClock(LL_AHB2_GRP1_PERIPH_GPIOC);
  LL_AHB2_GRP1_EnableClock(LL_AHB2_GRP1_PERIPH_GPIOB);
  /**SPI2 GPIO Configuration
  PC1   ------> SPI2_MOSI
  PC2   ------> SPI2_MISO
  PB10   ------> SPI2_SCK
  */
  GPIO_InitStruct.Pin = LL_GPIO_PIN_1|LL_GPIO_PIN_2;
  GPIO_InitStruct.Mode = LL_GPIO_MODE_ALTERNATE;
  GPIO_InitStruct.Speed = LL_GPIO_SPEED_FREQ_LOW;
  GPIO_InitStruct.OutputType = LL_GPIO_OUTPUT_PUSHPULL;
  GPIO_InitStruct.Pull = LL_GPIO_PULL_NO;
  GPIO_InitStruct.Alternate = LL_GPIO_AF_5;
  LL_GPIO_Init(GPIOC, &GPIO_InitStruct);

  GPIO_InitStruct.Pin = LL_GPIO_PIN_10;
  GPIO_InitStruct.Mode = LL_GPIO_MODE_ALTERNATE;
  GPIO_InitStruct.Speed = LL_GPIO_SPEED_FREQ_LOW;
  GPIO_InitStruct.OutputType = LL_GPIO_OUTPUT_PUSHPULL;
  GPIO_InitStruct.Pull = LL_GPIO_PULL_NO;
  GPIO_InitStruct.Alternate = LL_GPIO_AF_5;
  LL_GPIO_Init(GPIOB, &GPIO_InitStruct);

  /* SPI2 parameter configuration*/
  SPI_InitStruct.TransferDirection = LL_SPI_FULL_DUPLEX;
  SPI_InitStruct.Mode = LL_SPI_MODE_MASTER;
  SPI_InitStruct.DataWidth = LL_SPI_DATAWIDTH_8BIT;
  SPI_InitStruct.ClockPolarity = LL_SPI_POLARITY_LOW;
  SPI_InitStruct.ClockPhase = LL_SPI_PHASE_1EDGE;
  SPI_InitStruct.NSS = LL_SPI_NSS_SOFT;
  SPI_InitStruct.BaudRate = LL_SPI_BAUDRATEPRESCALER_DIV16;
  SPI_InitStruct.BitOrder = LL_SPI_MSB_FIRST;
  SPI_InitStruct.CRCCalculation = LL_SPI_CRCCALCULATION_DISABLE;
  SPI_InitStruct.CRCPoly = 0x7;
  LL_SPI_Init(SPI2, &SPI_InitStruct);
  LL_SPI_SetStandard(SPI2, LL_SPI_PROTOCOL_MOTOROLA);
  LL_SPI_EnableNSSPulseMgt(SPI2);
  /* USER CODE BEGIN SPI2_Init 2 */
  LL_SPI_SetFIFOThreshold(SPI2, LL_SPI_FIFO_TH_01DATA);
  /* USER CODE END SPI2_Init 2 */

}

static void MX_TIM1_Init(void)
{

  LL_TIM_InitTypeDef TIM_InitStruct = {0};
  LL_TIM_OC_InitTypeDef TIM_OC_InitStruct = {0};
  LL_TIM_BDTR_InitTypeDef TIM_BDTRInitStruct = {0};

  LL_GPIO_InitTypeDef GPIO_InitStruct = {0};

  /* Peripheral clock enable */
  LL_APB2_GRP1_EnableClock(LL_APB2_GRP1_PERIPH_TIM1);

  TIM_InitStruct.Prescaler = 59;
  TIM_InitStruct.CounterMode = LL_TIM_COUNTERMODE_UP;
  TIM_InitStruct.Autoreload = 12011;
  TIM_InitStruct.ClockDivision = LL_TIM_CLOCKDIVISION_DIV1;
  TIM_InitStruct.RepetitionCounter = 0;
  LL_TIM_Init(TIM1, &TIM_InitStruct);
  LL_TIM_DisableARRPreload(TIM1);
  LL_TIM_SetClockSource(TIM1, LL_TIM_CLOCKSOURCE_INTERNAL);
  LL_TIM_OC_EnablePreload(TIM1, LL_TIM_CHANNEL_CH1);
  TIM_OC_InitStruct.OCMode = LL_TIM_OCMODE_PWM1;
  TIM_OC_InitStruct.OCState = LL_TIM_OCSTATE_DISABLE;
  TIM_OC_InitStruct.OCNState = LL_TIM_OCSTATE_DISABLE;
  TIM_OC_InitStruct.CompareValue = 0;
  TIM_OC_InitStruct.OCPolarity = LL_TIM_OCPOLARITY_HIGH;
  TIM_OC_InitStruct.OCNPolarity = LL_TIM_OCPOLARITY_HIGH;
  TIM_OC_InitStruct.OCIdleState = LL_TIM_OCIDLESTATE_LOW;
  TIM_OC_InitStruct.OCNIdleState = LL_TIM_OCIDLESTATE_LOW;
  LL_TIM_OC_Init(TIM1, LL_TIM_CHANNEL_CH1, &TIM_OC_InitStruct);
  LL_TIM_OC_DisableFast(TIM1, LL_TIM_CHANNEL_CH1);
  LL_TIM_OC_EnablePreload(TIM1, LL_TIM_CHANNEL_CH2);
  LL_TIM_OC_Init(TIM1, LL_TIM_CHANNEL_CH2, &TIM_OC_InitStruct);
  LL_TIM_OC_DisableFast(TIM1, LL_TIM_CHANNEL_CH2);
  LL_TIM_OC_EnablePreload(TIM1, LL_TIM_CHANNEL_CH3);
  LL_TIM_OC_Init(TIM1, LL_TIM_CHANNEL_CH3, &TIM_OC_InitStruct);
  LL_TIM_OC_DisableFast(TIM1, LL_TIM_CHANNEL_CH3);
  LL_TIM_SetTriggerOutput(TIM1, LL_TIM_TRGO_RESET);
  LL_TIM_SetTriggerOutput2(TIM1, LL_TIM_TRGO2_RESET);
  LL_TIM_DisableMasterSlaveMode(TIM1);
  TIM_BDTRInitStruct.OSSRState = LL_TIM_OSSR_DISABLE;
  TIM_BDTRInitStruct.OSSIState = LL_TIM_OSSI_DISABLE;
  TIM_BDTRInitStruct.LockLevel = LL_TIM_LOCKLEVEL_OFF;
  TIM_BDTRInitStruct.DeadTime = 0;
  TIM_BDTRInitStruct.BreakState = LL_TIM_BREAK_DISABLE;
  TIM_BDTRInitStruct.BreakPolarity = LL_TIM_BREAK_POLARITY_HIGH;
  TIM_BDTRInitStruct.BreakFilter = LL_TIM_BREAK_FILTER_FDIV1;
  TIM_BDTRInitStruct.BreakAFMode = LL_TIM_BREAK_AFMODE_INPUT;
  TIM_BDTRInitStruct.Break2State = LL_TIM_BREAK2_DISABLE;
  TIM_BDTRInitStruct.Break2Polarity = LL_TIM_BREAK2_POLARITY_HIGH;
  TIM_BDTRInitStruct.Break2Filter = LL_TIM_BREAK2_FILTER_FDIV1;
  TIM_BDTRInitStruct.Break2AFMode = LL_TIM_BREAK_AFMODE_INPUT;
  TIM_BDTRInitStruct.AutomaticOutput = LL_TIM_AUTOMATICOUTPUT_DISABLE;
  LL_TIM_BDTR_Init(TIM1, &TIM_BDTRInitStruct);
  LL_AHB2_GRP1_EnableClock(LL_AHB2_GRP1_PERIPH_GPIOA);
  /**TIM1 GPIO Configuration
  PA8   ------> TIM1_CH1
  PA9   ------> TIM1_CH2
  PA10   ------> TIM1_CH3
  */
  GPIO_InitStruct.Pin = LL_GPIO_PIN_8|LL_GPIO_PIN_9|LL_GPIO_PIN_10;
  GPIO_InitStruct.Mode = LL_GPIO_MODE_ALTERNATE;
  GPIO_InitStruct.Speed = LL_GPIO_SPEED_FREQ_LOW;
  GPIO_InitStruct.OutputType = LL_GPIO_OUTPUT_PUSHPULL;
  GPIO_InitStruct.Pull = LL_GPIO_PULL_NO;
  GPIO_InitStruct.Alternate = LL_GPIO_AF_1;
  LL_GPIO_Init(GPIOA, &GPIO_InitStruct);

}

static void MX_TIM2_Init(void)
{

  LL_TIM_InitTypeDef TIM_InitStruct = {0};

  LL_GPIO_InitTypeDef GPIO_InitStruct = {0};

  /* Peripheral clock enable */
  LL_APB1_GRP1_EnableClock(LL_APB1_GRP1_PERIPH_TIM2);

  LL_AHB2_GRP1_EnableClock(LL_AHB2_GRP1_PERIPH_GPIOA);
  /**TIM2 GPIO Configuration
  PA1   ------> TIM2_CH2
  PA5   ------> TIM2_CH1
  */
  GPIO_InitStruct.Pin = LL_GPIO_PIN_1|LL_GPIO_PIN_5;
  GPIO_InitStruct.Mode = LL_GPIO_MODE_ALTERNATE;
  GPIO_InitStruct.Speed = LL_GPIO_SPEED_FREQ_LOW;
  GPIO_InitStruct.OutputType = LL_GPIO_OUTPUT_PUSHPULL;
  GPIO_InitStruct.Pull = LL_GPIO_PULL_NO;
  GPIO_InitStruct.Alternate = LL_GPIO_AF_1;
  LL_GPIO_Init(GPIOA, &GPIO_InitStruct);

  TIM_InitStruct.Prescaler = 59;
  TIM_InitStruct.CounterMode = LL_TIM_COUNTERMODE_UP;
  TIM_InitStruct.Autoreload = 4294967295;
  TIM_InitStruct.ClockDivision = LL_TIM_CLOCKDIVISION_DIV1;
  LL_TIM_Init(TIM2, &TIM_InitStruct);
  LL_TIM_DisableARRPreload(TIM2);
  LL_TIM_SetClockSource(TIM2, LL_TIM_CLOCKSOURCE_INTERNAL);
  LL_TIM_SetTriggerOutput(TIM2, LL_TIM_TRGO_RESET);
  LL_TIM_DisableMasterSlaveMode(TIM2);
  LL_TIM_IC_SetActiveInput(TIM2, LL_TIM_CHANNEL_CH1, LL_TIM_ACTIVEINPUT_DIRECTTI);
  LL_TIM_IC_SetPrescaler(TIM2, LL_TIM_CHANNEL_CH1, LL_TIM_ICPSC_DIV1);
  LL_TIM_IC_SetFilter(TIM2, LL_TIM_CHANNEL_CH1, LL_TIM_IC_FILTER_FDIV1);
  LL_TIM_IC_SetPolarity(TIM2, LL_TIM_CHANNEL_CH1, LL_TIM_IC_POLARITY_RISING);
  LL_TIM_IC_SetActiveInput(TIM2, LL_TIM_CHANNEL_CH2, LL_TIM_ACTIVEINPUT_DIRECTTI);
  LL_TIM_IC_SetPrescaler(TIM2, LL_TIM_CHANNEL_CH2, LL_TIM_ICPSC_DIV1);
  LL_TIM_IC_SetFilter(TIM2, LL_TIM_CHANNEL_CH2, LL_TIM_IC_FILTER_FDIV1);
  LL_TIM_IC_SetPolarity(TIM2, LL_TIM_CHANNEL_CH2, LL_TIM_IC_POLARITY_RISING);

}

static void MX_TIM3_Init(void)
{

  LL_TIM_InitTypeDef TIM_InitStruct = {0};
  LL_TIM_OC_InitTypeDef TIM_OC_InitStruct = {0};

  LL_GPIO_InitTypeDef GPIO_InitStruct = {0};

  /* Peripheral clock enable */
  LL_APB1_GRP1_EnableClock(LL_APB1_GRP1_PERIPH_TIM3);

  TIM_InitStruct.Prescaler = 59;
  TIM_InitStruct.CounterMode = LL_TIM_COUNTERMODE_UP;
  TIM_InitStruct.Autoreload = 12011;
  TIM_InitStruct.ClockDivision = LL_TIM_CLOCKDIVISION_DIV1;
  LL_TIM_Init(TIM3, &TIM_InitStruct);
  LL_TIM_DisableARRPreload(TIM3);
  LL_TIM_SetClockSource(TIM3, LL_TIM_CLOCKSOURCE_INTERNAL);
  LL_TIM_OC_EnablePreload(TIM3, LL_TIM_CHANNEL_CH1);
  TIM_OC_InitStruct.OCMode = LL_TIM_OCMODE_PWM1;
  TIM_OC_InitStruct.OCState = LL_TIM_OCSTATE_DISABLE;
  TIM_OC_InitStruct.OCNState = LL_TIM_OCSTATE_DISABLE;
  TIM_OC_InitStruct.CompareValue = 0;
  TIM_OC_InitStruct.OCPolarity = LL_TIM_OCPOLARITY_HIGH;
  LL_TIM_OC_Init(TIM3, LL_TIM_CHANNEL_CH1, &TIM_OC_InitStruct);
  LL_TIM_OC_DisableFast(TIM3, LL_TIM_CHANNEL_CH1);
  LL_TIM_OC_EnablePreload(TIM3, LL_TIM_CHANNEL_CH2);
  LL_TIM_OC_Init(TIM3, LL_TIM_CHANNEL_CH2, &TIM_OC_InitStruct);
  LL_TIM_OC_DisableFast(TIM3, LL_TIM_CHANNEL_CH2);
  LL_TIM_OC_EnablePreload(TIM3, LL_TIM_CHANNEL_CH3);
  LL_TIM_OC_Init(TIM3, LL_TIM_CHANNEL_CH3, &TIM_OC_InitStruct);
  LL_TIM_OC_DisableFast(TIM3, LL_TIM_CHANNEL_CH3);
  LL_TIM_OC_EnablePreload(TIM3, LL_TIM_CHANNEL_CH4);
  LL_TIM_OC_Init(TIM3, LL_TIM_CHANNEL_CH4, &TIM_OC_InitStruct);
  LL_TIM_OC_DisableFast(TIM3, LL_TIM_CHANNEL_CH4);
  LL_TIM_SetTriggerOutput(TIM3, LL_TIM_TRGO_RESET);
  LL_TIM_DisableMasterSlaveMode(TIM3);
  LL_AHB2_GRP1_EnableClock(LL_AHB2_GRP1_PERIPH_GPIOB);
  /**TIM3 GPIO Configuration
  PB0   ------> TIM3_CH3
  PB1   ------> TIM3_CH4
  PB4(NJTRST)   ------> TIM3_CH1
  PB5   ------> TIM3_CH2
  */
  GPIO_InitStruct.Pin = LL_GPIO_PIN_0|LL_GPIO_PIN_1|LL_GPIO_PIN_4|LL_GPIO_PIN_5;
  GPIO_InitStruct.Mode = LL_GPIO_MODE_ALTERNATE;
  GPIO_InitStruct.Speed = LL_GPIO_SPEED_FREQ_LOW;
  GPIO_InitStruct.OutputType = LL_GPIO_OUTPUT_PUSHPULL;
  GPIO_InitStruct.Pull = LL_GPIO_PULL_NO;
  GPIO_InitStruct.Alternate = LL_GPIO_AF_2;
  LL_GPIO_Init(GPIOB, &GPIO_InitStruct);

}

static void MX_TIM4_Init(void)
{

  LL_TIM_InitTypeDef TIM_InitStruct = {0};
  LL_TIM_OC_InitTypeDef TIM_OC_InitStruct = {0};

  LL_GPIO_InitTypeDef GPIO_InitStruct = {0};

  /* Peripheral clock enable */
  LL_APB1_GRP1_EnableClock(LL_APB1_GRP1_PERIPH_TIM4);

  TIM_InitStruct.Prescaler = 59;
  TIM_InitStruct.CounterMode = LL_TIM_COUNTERMODE_UP;
  TIM_InitStruct.Autoreload = 7142;
  TIM_InitStruct.ClockDivision = LL_TIM_CLOCKDIVISION_DIV1;
  LL_TIM_Init(TIM4, &TIM_InitStruct);
  LL_TIM_DisableARRPreload(TIM4);
  LL_TIM_SetClockSource(TIM4, LL_TIM_CLOCKSOURCE_INTERNAL);
  LL_TIM_OC_EnablePreload(TIM4, LL_TIM_CHANNEL_CH1);
  TIM_OC_InitStruct.OCMode = LL_TIM_OCMODE_PWM1;
  TIM_OC_InitStruct.OCState = LL_TIM_OCSTATE_DISABLE;
  TIM_OC_InitStruct.OCNState = LL_TIM_OCSTATE_DISABLE;
  TIM_OC_InitStruct.CompareValue = 0;
  TIM_OC_InitStruct.OCPolarity = LL_TIM_OCPOLARITY_HIGH;
  LL_TIM_OC_Init(TIM4, LL_TIM_CHANNEL_CH1, &TIM_OC_InitStruct);
  LL_TIM_OC_DisableFast(TIM4, LL_TIM_CHANNEL_CH1);
  LL_TIM_SetTriggerOutput(TIM4, LL_TIM_TRGO_RESET);
  LL_TIM_DisableMasterSlaveMode(TIM4);
  LL_AHB2_GRP1_EnableClock(LL_AHB2_GRP1_PERIPH_GPIOB);
  /**TIM4 GPIO Configuration
  PB6   ------> TIM4_CH1
  */
  GPIO_InitStruct.Pin = LL_GPIO_PIN_6;
  GPIO_InitStruct.Mode = LL_GPIO_MODE_ALTERNATE;
  GPIO_InitStruct.Speed = LL_GPIO_SPEED_FREQ_LOW;
  GPIO_InitStruct.OutputType = LL_GPIO_OUTPUT_PUSHPULL;
  GPIO_InitStruct.Pull = LL_GPIO_PULL_NO;
  GPIO_InitStruct.Alternate = LL_GPIO_AF_2;
  LL_GPIO_Init(GPIOB, &GPIO_InitStruct);

}

static void MX_TIM8_Init(void)
{

  TIM_ClockConfigTypeDef sClockSourceConfig = {0};
  TIM_MasterConfigTypeDef sMasterConfig = {0};
  TIM_OC_InitTypeDef sConfigOC = {0};
  TIM_BreakDeadTimeConfigTypeDef sBreakDeadTimeConfig = {0};

  htim8.Instance = TIM8;
  htim8.Init.Prescaler = 59;
  htim8.Init.CounterMode = TIM_COUNTERMODE_UP;
  htim8.Init.Period = 12011;
  htim8.Init.ClockDivision = TIM_CLOCKDIVISION_DIV1;
  htim8.Init.RepetitionCounter = 0;
  htim8.Init.AutoReloadPreload = TIM_AUTORELOAD_PRELOAD_DISABLE;
  if (HAL_TIM_Base_Init(&htim8) != HAL_OK)
  {
    Error_Handler();
  }
  sClockSourceConfig.ClockSource = TIM_CLOCKSOURCE_INTERNAL;
  if (HAL_TIM_ConfigClockSource(&htim8, &sClockSourceConfig) != HAL_OK)
  {
    Error_Handler();
  }
  if (HAL_TIM_PWM_Init(&htim8) != HAL_OK)
  {
    Error_Handler();
  }
  sMasterConfig.MasterOutputTrigger = TIM_TRGO_RESET;
  sMasterConfig.MasterOutputTrigger2 = TIM_TRGO2_RESET;
  sMasterConfig.MasterSlaveMode = TIM_MASTERSLAVEMODE_DISABLE;
  if (HAL_TIMEx_MasterConfigSynchronization(&htim8, &sMasterConfig) != HAL_OK)
  {
    Error_Handler();
  }
  sConfigOC.OCMode = TIM_OCMODE_PWM1;
  sConfigOC.Pulse = 0;
  sConfigOC.OCPolarity = TIM_OCPOLARITY_HIGH;
  sConfigOC.OCNPolarity = TIM_OCNPOLARITY_HIGH;
  sConfigOC.OCFastMode = TIM_OCFAST_DISABLE;
  sConfigOC.OCIdleState = TIM_OCIDLESTATE_RESET;
  sConfigOC.OCNIdleState = TIM_OCNIDLESTATE_RESET;
  if (HAL_TIM_PWM_ConfigChannel(&htim8, &sConfigOC, TIM_CHANNEL_3) != HAL_OK)
  {
    Error_Handler();
  }
  sBreakDeadTimeConfig.OffStateRunMode = TIM_OSSR_DISABLE;
  sBreakDeadTimeConfig.OffStateIDLEMode = TIM_OSSI_DISABLE;
  sBreakDeadTimeConfig.LockLevel = TIM_LOCKLEVEL_OFF;
  sBreakDeadTimeConfig.DeadTime = 0;
  sBreakDeadTimeConfig.BreakState = TIM_BREAK_DISABLE;
  sBreakDeadTimeConfig.BreakPolarity = TIM_BREAKPOLARITY_HIGH;
  sBreakDeadTimeConfig.BreakFilter = 0;
  sBreakDeadTimeConfig.BreakAFMode = TIM_BREAK_AFMODE_INPUT;
  sBreakDeadTimeConfig.Break2State = TIM_BREAK2_DISABLE;
  sBreakDeadTimeConfig.Break2Polarity = TIM_BREAK2POLARITY_HIGH;
  sBreakDeadTimeConfig.Break2Filter = 0;
  sBreakDeadTimeConfig.Break2AFMode = TIM_BREAK_AFMODE_INPUT;
  sBreakDeadTimeConfig.AutomaticOutput = TIM_AUTOMATICOUTPUT_DISABLE;
  if (HAL_TIMEx_ConfigBreakDeadTime(&htim8, &sBreakDeadTimeConfig) != HAL_OK)
  {
    Error_Handler();
  }
  HAL_TIM_MspPostInit(&htim8);

}

static void MX_UART4_Init(void)
{

  huart4.Instance = UART4;
  huart4.Init.BaudRate = 115200;
  huart4.Init.WordLength = UART_WORDLENGTH_8B;
  huart4.Init.StopBits = UART_STOPBITS_1;
  huart4.Init.Parity = UART_PARITY_NONE;
  huart4.Init.Mode = UART_MODE_TX_RX;
  huart4.Init.HwFlowCtl = UART_HWCONTROL_NONE;
  huart4.Init.OverSampling = UART_OVERSAMPLING_16;
  huart4.Init.OneBitSampling = UART_ONE_BIT_SAMPLE_DISABLE;
  huart4.Init.ClockPrescaler = UART_PRESCALER_DIV1;
  huart4.AdvancedInit.AdvFeatureInit = UART_ADVFEATURE_NO_INIT;
  if (HAL_UART_Init(&huart4) != HAL_OK)
  {
    Error_Handler();
  }
  if (HAL_UARTEx_SetTxFifoThreshold(&huart4, UART_TXFIFO_THRESHOLD_1_8) != HAL_OK)
  {
    Error_Handler();
  }
  if (HAL_UARTEx_SetRxFifoThreshold(&huart4, UART_RXFIFO_THRESHOLD_1_8) != HAL_OK)
  {
    Error_Handler();
  }
  if (HAL_UARTEx_DisableFifoMode(&huart4) != HAL_OK)
  {
    Error_Handler();
  }

}

static void MX_UART5_Init(void)
{

  huart5.Instance = UART5;
  huart5.Init.BaudRate = 115200;
  huart5.Init.WordLength = UART_WORDLENGTH_8B;
  huart5.Init.StopBits = UART_STOPBITS_1;
  huart5.Init.Parity = UART_PARITY_NONE;
  huart5.Init.Mode = UART_MODE_TX_RX;
  huart5.Init.HwFlowCtl = UART_HWCONTROL_NONE;
  huart5.Init.OverSampling = UART_OVERSAMPLING_16;
  huart5.Init.OneBitSampling = UART_ONE_BIT_SAMPLE_DISABLE;
  huart5.Init.ClockPrescaler = UART_PRESCALER_DIV1;
  huart5.AdvancedInit.AdvFeatureInit = UART_ADVFEATURE_NO_INIT;
  if (HAL_HalfDuplex_Init(&huart5) != HAL_OK)
  {
    Error_Handler();
  }
  if (HAL_UARTEx_SetTxFifoThreshold(&huart5, UART_TXFIFO_THRESHOLD_1_8) != HAL_OK)
  {
    Error_Handler();
  }
  if (HAL_UARTEx_SetRxFifoThreshold(&huart5, UART_RXFIFO_THRESHOLD_1_8) != HAL_OK)
  {
    Error_Handler();
  }
  if (HAL_UARTEx_DisableFifoMode(&huart5) != HAL_OK)
  {
    Error_Handler();
  }

}

static void MX_UART7_Init(void)
{

  huart7.Instance = UART7;
  huart7.Init.BaudRate = 115200;
  huart7.Init.WordLength = UART_WORDLENGTH_8B;
  huart7.Init.StopBits = UART_STOPBITS_1;
  huart7.Init.Parity = UART_PARITY_NONE;
  huart7.Init.Mode = UART_MODE_TX_RX;
  huart7.Init.HwFlowCtl = UART_HWCONTROL_NONE;
  huart7.Init.OverSampling = UART_OVERSAMPLING_16;
  huart7.Init.OneBitSampling = UART_ONE_BIT_SAMPLE_DISABLE;
  huart7.Init.ClockPrescaler = UART_PRESCALER_DIV1;
  huart7.AdvancedInit.AdvFeatureInit = UART_ADVFEATURE_NO_INIT;
  if (HAL_HalfDuplex_Init(&huart7) != HAL_OK)
  {
    Error_Handler();
  }
  if (HAL_UARTEx_SetTxFifoThreshold(&huart7, UART_TXFIFO_THRESHOLD_1_8) != HAL_OK)
  {
    Error_Handler();
  }
  if (HAL_UARTEx_SetRxFifoThreshold(&huart7, UART_RXFIFO_THRESHOLD_1_8) != HAL_OK)
  {
    Error_Handler();
  }
  if (HAL_UARTEx_DisableFifoMode(&huart7) != HAL_OK)
  {
    Error_Handler();
  }

}

static void MX_USART1_UART_Init(void)
{

  huart1.Instance = USART1;
  huart1.Init.BaudRate = 115200;
  huart1.Init.WordLength = UART_WORDLENGTH_8B;
  huart1.Init.StopBits = UART_STOPBITS_1;
  huart1.Init.Parity = UART_PARITY_NONE;
  huart1.Init.Mode = UART_MODE_TX_RX;
  huart1.Init.HwFlowCtl = UART_HWCONTROL_NONE;
  huart1.Init.OverSampling = UART_OVERSAMPLING_16;
  huart1.Init.OneBitSampling = UART_ONE_BIT_SAMPLE_DISABLE;
  huart1.Init.ClockPrescaler = UART_PRESCALER_DIV1;
  huart1.AdvancedInit.AdvFeatureInit = UART_ADVFEATURE_NO_INIT;
  if (HAL_UART_Init(&huart1) != HAL_OK)
  {
    Error_Handler();
  }
  if (HAL_UARTEx_SetTxFifoThreshold(&huart1, UART_TXFIFO_THRESHOLD_1_8) != HAL_OK)
  {
    Error_Handler();
  }
  if (HAL_UARTEx_SetRxFifoThreshold(&huart1, UART_RXFIFO_THRESHOLD_1_8) != HAL_OK)
  {
    Error_Handler();
  }
  if (HAL_UARTEx_DisableFifoMode(&huart1) != HAL_OK)
  {
    Error_Handler();
  }

}

static void MX_USART2_UART_Init(void)
{

  huart2.Instance = USART2;
  huart2.Init.BaudRate = 115200;
  huart2.Init.WordLength = UART_WORDLENGTH_8B;
  huart2.Init.StopBits = UART_STOPBITS_1;
  huart2.Init.Parity = UART_PARITY_NONE;
  huart2.Init.Mode = UART_MODE_TX_RX;
  huart2.Init.HwFlowCtl = UART_HWCONTROL_NONE;
  huart2.Init.OverSampling = UART_OVERSAMPLING_16;
  huart2.Init.OneBitSampling = UART_ONE_BIT_SAMPLE_DISABLE;
  huart2.Init.ClockPrescaler = UART_PRESCALER_DIV1;
  huart2.AdvancedInit.AdvFeatureInit = UART_ADVFEATURE_NO_INIT;
  if (HAL_HalfDuplex_Init(&huart2) != HAL_OK)
  {
    Error_Handler();
  }
  if (HAL_UARTEx_SetTxFifoThreshold(&huart2, UART_TXFIFO_THRESHOLD_1_8) != HAL_OK)
  {
    Error_Handler();
  }
  if (HAL_UARTEx_SetRxFifoThreshold(&huart2, UART_RXFIFO_THRESHOLD_1_8) != HAL_OK)
  {
    Error_Handler();
  }
  if (HAL_UARTEx_DisableFifoMode(&huart2) != HAL_OK)
  {
    Error_Handler();
  }

}

static void MX_USART3_UART_Init(void)
{

  huart3.Instance = USART3;
  huart3.Init.BaudRate = 115200;
  huart3.Init.WordLength = UART_WORDLENGTH_8B;
  huart3.Init.StopBits = UART_STOPBITS_1;
  huart3.Init.Parity = UART_PARITY_NONE;
  huart3.Init.Mode = UART_MODE_TX_RX;
  huart3.Init.HwFlowCtl = UART_HWCONTROL_NONE;
  huart3.Init.OverSampling = UART_OVERSAMPLING_16;
  huart3.Init.OneBitSampling = UART_ONE_BIT_SAMPLE_DISABLE;
  huart3.Init.ClockPrescaler = UART_PRESCALER_DIV1;
  huart3.AdvancedInit.AdvFeatureInit = UART_ADVFEATURE_NO_INIT;
  if (HAL_UART_Init(&huart3) != HAL_OK)
  {
    Error_Handler();
  }
  if (HAL_UARTEx_SetTxFifoThreshold(&huart3, UART_TXFIFO_THRESHOLD_1_8) != HAL_OK)
  {
    Error_Handler();
  }
  if (HAL_UARTEx_SetRxFifoThreshold(&huart3, UART_RXFIFO_THRESHOLD_1_8) != HAL_OK)
  {
    Error_Handler();
  }
  if (HAL_UARTEx_DisableFifoMode(&huart3) != HAL_OK)
  {
    Error_Handler();
  }

}

static void MX_USART6_UART_Init(void)
{

  huart6.Instance = USART6;
  huart6.Init.BaudRate = 115200;
  huart6.Init.WordLength = UART_WORDLENGTH_8B;
  huart6.Init.StopBits = UART_STOPBITS_1;
  huart6.Init.Parity = UART_PARITY_NONE;
  huart6.Init.Mode = UART_MODE_TX_RX;
  huart6.Init.HwFlowCtl = UART_HWCONTROL_NONE;
  huart6.Init.OverSampling = UART_OVERSAMPLING_16;
  huart6.Init.OneBitSampling = UART_ONE_BIT_SAMPLE_DISABLE;
  huart6.Init.ClockPrescaler = UART_PRESCALER_DIV1;
  huart6.AdvancedInit.AdvFeatureInit = UART_ADVFEATURE_NO_INIT;
  if (HAL_UART_Init(&huart6) != HAL_OK)
  {
    Error_Handler();
  }
  if (HAL_UARTEx_SetTxFifoThreshold(&huart6, UART_TXFIFO_THRESHOLD_1_8) != HAL_OK)
  {
    Error_Handler();
  }
  if (HAL_UARTEx_SetRxFifoThreshold(&huart6, UART_RXFIFO_THRESHOLD_1_8) != HAL_OK)
  {
    Error_Handler();
  }
  if (HAL_UARTEx_DisableFifoMode(&huart6) != HAL_OK)
  {
    Error_Handler();
  }

}

static void MX_USB_PCD_Init(void)
{

  hpcd_USB_DRD_FS.Instance = USB_DRD_FS;
  hpcd_USB_DRD_FS.Init.dev_endpoints = 8;
  hpcd_USB_DRD_FS.Init.speed = USBD_FS_SPEED;
  hpcd_USB_DRD_FS.Init.phy_itface = PCD_PHY_EMBEDDED;
  hpcd_USB_DRD_FS.Init.Sof_enable = DISABLE;
  hpcd_USB_DRD_FS.Init.low_power_enable = DISABLE;
  hpcd_USB_DRD_FS.Init.lpm_enable = DISABLE;
  hpcd_USB_DRD_FS.Init.battery_charging_enable = DISABLE;
  hpcd_USB_DRD_FS.Init.vbus_sensing_enable = DISABLE;
  hpcd_USB_DRD_FS.Init.bulk_doublebuffer_enable = DISABLE;
  hpcd_USB_DRD_FS.Init.iso_singlebuffer_enable = DISABLE;
  if (HAL_PCD_Init(&hpcd_USB_DRD_FS) != HAL_OK)
  {
    Error_Handler();
  }

}

static void MX_GPIO_Init(void)
{
  LL_GPIO_InitTypeDef GPIO_InitStruct = {0};

  /* GPIO Ports Clock Enable */
  LL_AHB2_GRP1_EnableClock(LL_AHB2_GRP1_PERIPH_GPIOC);
  LL_AHB2_GRP1_EnableClock(LL_AHB2_GRP1_PERIPH_GPIOH);
  LL_AHB2_GRP1_EnableClock(LL_AHB2_GRP1_PERIPH_GPIOA);
  LL_AHB2_GRP1_EnableClock(LL_AHB2_GRP1_PERIPH_GPIOB);
  LL_AHB2_GRP1_EnableClock(LL_AHB2_GRP1_PERIPH_GPIOD);

  /**/
  LL_GPIO_ResetOutputPin(GPIOC, LED1_Pin|LED2_Pin|IMU2_CS_Pin);

  /**/
  LL_GPIO_ResetOutputPin(IMU_CS_GPIO_Port, IMU_CS_Pin);

  /**/
  LL_GPIO_ResetOutputPin(GPIOB, CSB_Pin|CSB_MAG_Pin|DRDY_MAG_Pin);

  /**/
  LL_GPIO_ResetOutputPin(GPIOD, LL_GPIO_PIN_2);

  /**/
  GPIO_InitStruct.Pin = INT_BMP_Pin|IMU_INT_Pin;
  GPIO_InitStruct.Mode = LL_GPIO_MODE_INPUT;
  GPIO_InitStruct.Pull = LL_GPIO_PULL_NO;
  LL_GPIO_Init(GPIOC, &GPIO_InitStruct);

  /**/
  GPIO_InitStruct.Pin = LED1_Pin|LED2_Pin|IMU2_CS_Pin;
  GPIO_InitStruct.Mode = LL_GPIO_MODE_OUTPUT;
  GPIO_InitStruct.Speed = LL_GPIO_SPEED_FREQ_LOW;
  GPIO_InitStruct.OutputType = LL_GPIO_OUTPUT_PUSHPULL;
  GPIO_InitStruct.Pull = LL_GPIO_PULL_NO;
  LL_GPIO_Init(GPIOC, &GPIO_InitStruct);

  /**/
  GPIO_InitStruct.Pin = IMU_CS_Pin;
  GPIO_InitStruct.Mode = LL_GPIO_MODE_OUTPUT;
  GPIO_InitStruct.Speed = LL_GPIO_SPEED_FREQ_LOW;
  GPIO_InitStruct.OutputType = LL_GPIO_OUTPUT_PUSHPULL;
  GPIO_InitStruct.Pull = LL_GPIO_PULL_NO;
  LL_GPIO_Init(IMU_CS_GPIO_Port, &GPIO_InitStruct);

  /**/
  GPIO_InitStruct.Pin = CSB_Pin|CSB_MAG_Pin|DRDY_MAG_Pin;
  GPIO_InitStruct.Mode = LL_GPIO_MODE_OUTPUT;
  GPIO_InitStruct.Speed = LL_GPIO_SPEED_FREQ_LOW;
  GPIO_InitStruct.OutputType = LL_GPIO_OUTPUT_PUSHPULL;
  GPIO_InitStruct.Pull = LL_GPIO_PULL_NO;
  LL_GPIO_Init(GPIOB, &GPIO_InitStruct);

  /**/
  GPIO_InitStruct.Pin = LL_GPIO_PIN_2;
  GPIO_InitStruct.Mode = LL_GPIO_MODE_OUTPUT;
  GPIO_InitStruct.Speed = LL_GPIO_SPEED_FREQ_LOW;
  GPIO_InitStruct.OutputType = LL_GPIO_OUTPUT_PUSHPULL;
  GPIO_InitStruct.Pull = LL_GPIO_PULL_NO;
  LL_GPIO_Init(GPIOD, &GPIO_InitStruct);

}

void Error_Handler(void)
{
  __disable_irq();
  while (1)
  {
  }
}
